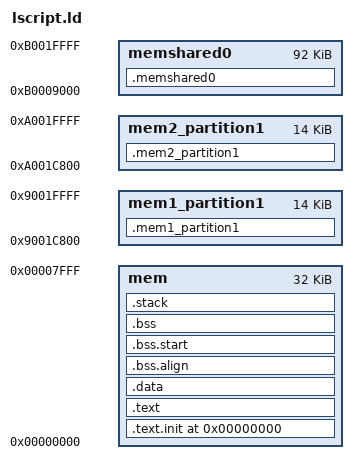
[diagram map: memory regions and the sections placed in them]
/* DO NOT EDIT
 * this file was automatically generated by ../../tools/generate-json from ../vep-config.txt for
 * VEP_ID=1 TILE_ID=0 PARTITION_ID=1
 */

MEMORY {
mem : ORIGIN = 0x0, LENGTH = 0x00008000 /* remove shared partition region, starting after the stack at LENGTH */
mem1_partition1 : ORIGIN = 0x9001C800, LENGTH = 0x00003800 /* vep=1 tile=1 partition=1 private shared memory region */
mem2_partition1 : ORIGIN = 0xA001C800, LENGTH = 0x00003800 /* vep=1 tile=2 partition=1 private shared memory region */
memshared0 : ORIGIN = 0xB0009000, LENGTH = 0x00017000 /* vep=1 private shared memory region */
}
_STACK_SIZE = 0x00004000;
OUTPUT_ARCH( "riscv" )
ENTRY( _start )
_STACK_SIZE = DEFINED(_STACK_SIZE) ? _STACK_SIZE : 0x1000;
SECTIONS
{
  . = 0x00000000;
  .text.init : { *(.text.init) } > mem
  .text : { *(.text) } > mem
  .data : { *(.data) } > mem
  .bss.align :
   {
           . = ALIGN(4);
           _bss = .;
   } > mem
   .bss.start :
   {
          _bss_lma = LOADADDR(.bss.start);
   } >mem
   .bss :
   {
           *(.sbss*)
           *(.gnu.linkonce.sb.*)
           *(.bss .bss.*)
           *(.gnu.linkonce.b.*)
           *(COMMON)
        . = ALIGN(4);
        _ebss = .;
   } >mem
  .mem1_partition1 : { *(.mem1_partition1) } > mem1_partition1
  .mem2_partition1 : { *(.mem2_partition1) } > mem2_partition1
  .memshared0 : { *(.memshared0) } > memshared0
  _end = .;
  .stack (NOLOAD) : {
          _stack_end = .;
          . += _STACK_SIZE;
          . = ALIGN(16);
          _stack_start = .;
  } > mem
  PROVIDE (end = .);
}
